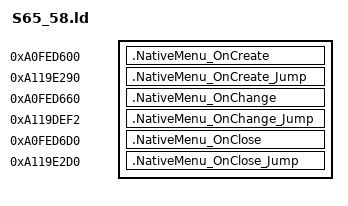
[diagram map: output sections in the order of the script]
SECTIONS {

    .NativeMenu_OnCreate 0xA0FED600 : {
        KEEP(*(.text.NativeMenu_OnCreate))
    }
    .NativeMenu_OnCreate_Jump 0xA119E290 : {
        KEEP(*(.text.NativeMenu_OnCreate_Jump))
    }

    .NativeMenu_OnChange 0xA0FED660 : {
        KEEP(*(.text.NativeMenu_OnChange))
        KEEP(*(.rodata*))
    }
    .NativeMenu_OnChange_Jump 0xA119DEF2 : {
        KEEP(*(.text.NativeMenu_OnChange_Jump))
    }

    .NativeMenu_OnClose 0xA0FED6D0 : {
        KEEP(*(.text.NativeMenu_OnClose))
    }
    .NativeMenu_OnClose_Jump 0xA119E2D0 : {
        KEEP(*(.text.NativeMenu_OnClose_Jump))
    }
}
